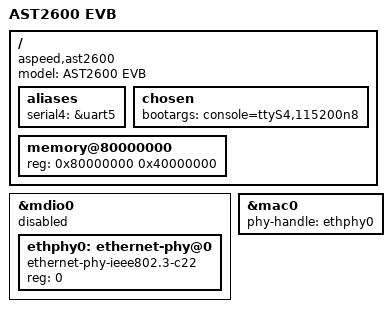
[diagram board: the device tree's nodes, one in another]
// SPDX-License-Identifier: GPL-2.0+
// Copyright 2019 IBM Corp.

/dts-v1/;

#include "aspeed-g6.dtsi"

/ {
        model = "AST2600 EVB";
        compatible = "aspeed,ast2600";

        aliases {
                serial4 = &uart5;
        };

        chosen {
                bootargs = "console=ttyS4,115200n8";
        };

        memory@80000000 {
                reg = <0x80000000 0x40000000>;
        };
};

&mdio0 {
        status = "enabled";

        ethphy0: ethernet-phy@0 {
                compatible = "ethernet-phy-ieee802.3-c22";
                reg = <0>;
        };
};

&mac0 {
        phy-handle = <&ethphy0>;
};
